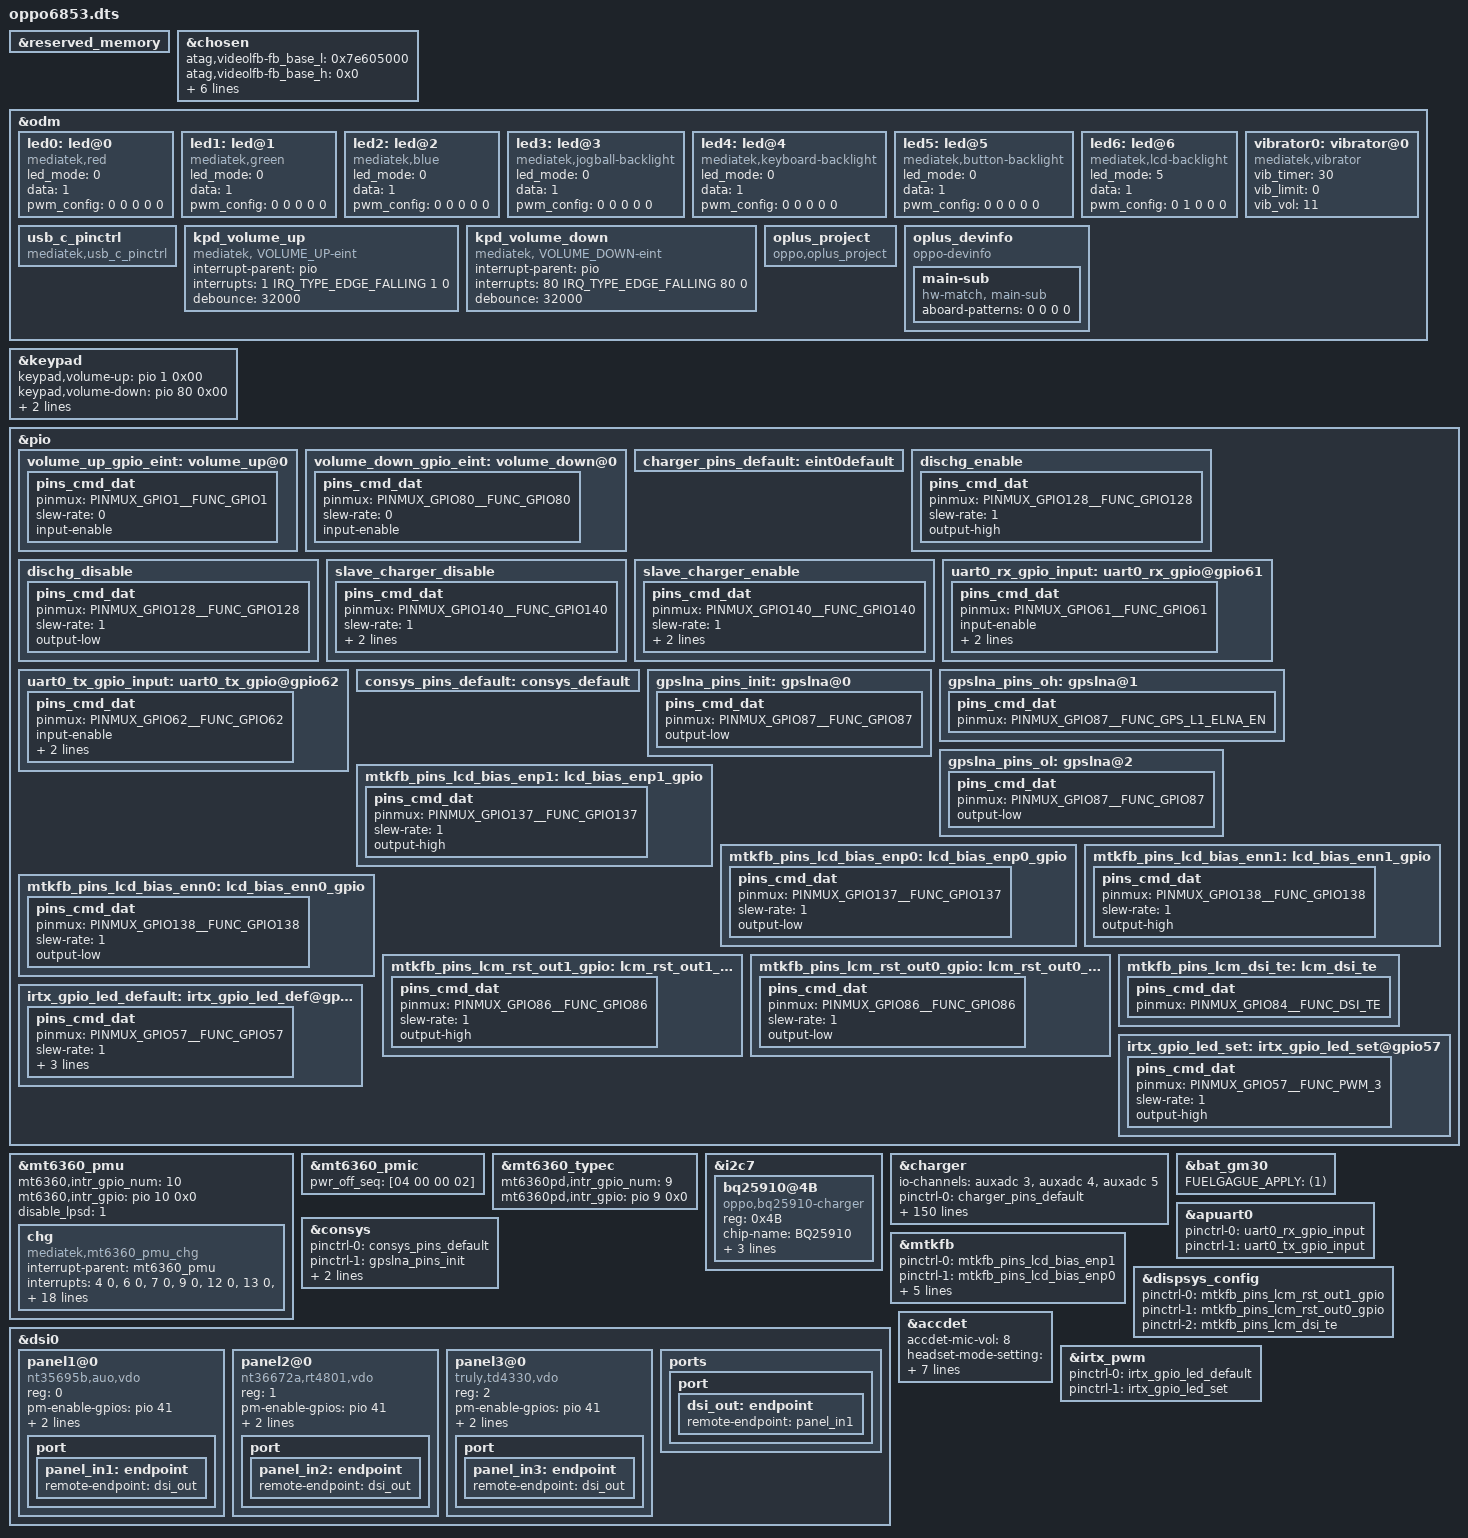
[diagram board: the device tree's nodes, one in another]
/*
 * Mediatek's mt6853 SoC device tree source
 *
 * Copyright (C) 2016 MediaTek Inc.
 *
 * This program is free software; you can redistribute it and/or modify
 * it under the terms of the GNU General Public License version 2 as
 * published by the Free Software Foundation.
 *
 * This program is distributed in the hope that it will be useful,
 * but WITHOUT ANY WARRANTY; without even the implied warranty of
 * MERCHANTABILITY or FITNESS FOR A PARTICULAR PURPOSE.
 * See http://www.gnu.org/licenses/gpl-2.0.html for more details.
 */
/dts-v1/;
/plugin/;
#include <dt-bindings/interrupt-controller/irq.h>
#include <dt-bindings/interrupt-controller/arm-gic.h>
#include <dt-bindings/pinctrl/mt6853-pinfunc.h>

&reserved_memory {
};

/* chosen */
&chosen {

	atag,videolfb-fb_base_l = <0x7e605000>;
	atag,videolfb-fb_base_h = <0x0>;
	atag,videolfb-islcmfound = <1>;
	atag,videolfb-islcm_inited = <0>;
	atag,videolfb-fps= <6000>;
	atag,videolfb-vramSize= <0x1be0000>;
	atag,videolfb-lcmname=
		"nt35595_fhd_dsi_cmd_truly_nt50358_drv";
};

&odm {
	led0:led@0 {
		compatible = "mediatek,red";
		led_mode = <0>;
		data = <1>;
		pwm_config = <0 0 0 0 0>;
	};
	led1:led@1 {
		compatible = "mediatek,green";
		led_mode = <0>;
		data = <1>;
		pwm_config = <0 0 0 0 0>;
	};
	led2:led@2 {
		compatible = "mediatek,blue";
		led_mode = <0>;
		data = <1>;
		pwm_config = <0 0 0 0 0>;
	};
	led3:led@3 {
		compatible = "mediatek,jogball-backlight";
		led_mode = <0>;
		data = <1>;
		pwm_config = <0 0 0 0 0>;
	};
	led4:led@4 {
		compatible = "mediatek,keyboard-backlight";
		led_mode = <0>;
		data = <1>;
		pwm_config = <0 0 0 0 0>;
	};
	led5:led@5 {
		compatible = "mediatek,button-backlight";
		led_mode = <0>;
		data = <1>;
		pwm_config = <0 0 0 0 0>;
	};
	led6:led@6 {
		compatible = "mediatek,lcd-backlight";
		led_mode = <5>;
		data = <1>;
		pwm_config = <0 1 0 0 0>;
	};
	vibrator0:vibrator@0 {
		compatible = "mediatek,vibrator";
		//#ifdef VENDOR_EDIT
		vib_timer = <30>;
		vib_limit = <0>;
		//#else
		//vib_timer = <25>;
		//vib_limit = <9>;
		//#endif /* VENDOR_EDIT */
		//#ifdef VENDOR_EDIT
		vib_vol= <11>;
		//#endif /* VENDOR_EDIT */
	};
	usb_c_pinctrl:usb_c_pinctrl {
		compatible = "mediatek,usb_c_pinctrl";
	};

/*VENDOR_EDIT keypad start*/
	kpd_volume_up:kpd_volume_up {
		compatible = "mediatek, VOLUME_UP-eint";
		interrupt-parent = <&pio>;
		interrupts = <1 IRQ_TYPE_EDGE_FALLING 1 0>;
		debounce = <32000>;
		status = "okay";
	};

	kpd_volume_down:kpd_volume_down {
		compatible = "mediatek, VOLUME_DOWN-eint";
		interrupt-parent = <&pio>;
		interrupts = <80 IRQ_TYPE_EDGE_FALLING 80 0>;
		debounce = <32000>;
		status = "okay";
	};
/*VENDOR_EDIT keypad end*/

	oplus_project:oplus_project {
		compatible = "oppo,oplus_project";
	};
	oplus_devinfo:oplus_devinfo {
		compatible = "oppo-devinfo";

		main-sub {
			compatible = "hw-match, main-sub";
			aboard-patterns = <0 0 0 0>;
			/*main board*/
			//match-projects = <19537 19538 19541 19539>;
		};
	};

};

/*VENDOR_EDIT*/
&keypad {
	keypad,volume-up	= <&pio 1 0x00>;
	keypad,volume-down	= <&pio 80 0x00>;
	pinctrl-names = "volume_up_as_int", "volume_down_as_int";
	pinctrl-0 = <&volume_up_gpio_eint>;
	pinctrl-1 = <&volume_down_gpio_eint>;
	status = "okay";
};
&pio {
	volume_up_gpio_eint:volume_up@0{
		pins_cmd_dat {
			pinmux = <PINMUX_GPIO1__FUNC_GPIO1>;
			slew-rate = <0>;  /*direction 0:in, 1:out*/
			input-enable;
		};
	};

	volume_down_gpio_eint:volume_down@0{
		pins_cmd_dat {
			pinmux = <PINMUX_GPIO80__FUNC_GPIO80>;
			slew-rate = <0>;  /*direction 0:in, 1:out*/
			input-enable;
		};
	};
};
/*VENDOR_EDIT*/
/* Charging Start */

&mt6360_pmu {
	mt6360,intr_gpio_num = <10>; /* direct defined GPIO num */
	mt6360,intr_gpio = <&pio 10 0x0>;
	//#ifdef VENDOR_EDIT
	disable_lpsd = <1>;
};

&mt6360_pmic {
	pwr_off_seq = [04 00 00 02];
};

&mt6360_typec {
	mt6360pd,intr_gpio_num = <9>; /* direct defined GPIO num */
	mt6360pd,intr_gpio = <&pio 9 0x0>;
	//mt6360pd,pcb_gpio = <&pio 57 0x0>;
	//mt6360pd,pcb_gpio_num = <57>;
};

&mt6360_pmu {
	chg {
		compatible = "mediatek,mt6360_pmu_chg";
		interrupt-parent = <&mt6360_pmu>;
		interrupts = <4 0>, <6 0>, <7 0>, <9 0>,
				<12 0>, <13 0>, <14 0>, <15 0>,
				<27 0>, <29 0>, <30 0>, <32 0>,
				<35 0>, <40 0>, <48 0>, <60 0>,
				<53 0>;
		interrupt-names = "chg_treg_evt", "chg_mivr_evt",
				"pwr_rdy_evt", "chg_batsysuv_evt",
				"chg_vsysuv_evt", "chg_vsysov_evt",
				"chg_vbatov_evt", "chg_vbusov_evt",
				"chg_tmri", "chg_adpbadi",
				"chg_rvpi",  "chg_aiccmeasl",
				"wdtmri", "pumpx_donei",
				"attachi", "chrdet_ext_evt",
				"hvdcp_det";
		io-channels = <&adc 0>, <&adc 1>, <&adc 3>, <&adc 4>,
				<&adc 5>, <&adc 6>, <&adc 8>, <&adc 10>;
		io-channel-names = "USBID", "VBUSDIV5", "VSYS", "VBAT",
				"IBUS", "IBAT", "TEMP_JC", "TS";
		chg_name = "primary_chg";
		ichg = <2000000>;               /* uA */
		aicr = <500000>;                /* uA */
		mivr = <4400000>;               /* uV */
		cv = <4350000>;                 /* uA */
		ieoc = <150000>;                /* uA */
		safety_timer = <12>;            /* hour */
		ircmp_resistor = <25000>;       /* uohm */
		ircmp_vclamp = <32000>;         /* uV */
		en_te = <1>;
		en_wdt = <1>;
		aicc_once = <1>;
		post_aicc = <1>;
		batoc_notify = <0>;
	};
};


&i2c7 {
	bq25910@4B{
		status = "okay";
		compatible = "oppo,bq25910-charger";
		reg = <0x4B>;
		chip-name = "BQ25910";

		pinctrl-names = "slave_charger_disable", "slave_charger_enable";
		pinctrl-0 = <&slave_charger_disable>;
		pinctrl-1 = <&slave_charger_enable>;

		qcom,slave-chg-en-gpio = <&pio 140 0x00>;
	};
};


&charger {
	io-channels =  <&auxadc 3>,<&auxadc 4>,
		<&auxadc 5>;
	io-channel-names = "auxadc3-chargeric_temp","auxadc4-usb_temp_v_l",
		"auxadc5-usb_temp_v_r";

	pinctrl-names = "default", "dischg_enable", "dischg_disable";
	pinctrl-0 = <&charger_pins_default>;
	pinctrl-1 = <&dischg_enable>;
	pinctrl-2 = <&dischg_disable>;

	//for oppo chg framework:
	qcom,input_current_charger_ma = <2000>;
        qcom,input_current_usb_ma = <500>;
        qcom,input_current_cdp_ma = <1500>;
        qcom,input_current_led_ma = <1200>;
        qcom,input_current_led_ma_high = <1000>;
        qcom,input_current_led_ma_warm = <1500>;
        qcom,input_current_led_ma_normal = <2000>;
        qcom,input_current_led_ma_forcmcc = <500>;
        qcom,input_current_camera_ma = <2000>;
        qcom,input_current_calling_ma = <1500>;
        qcom,qc_input_current_charger_ma = <2000>;

	qcom,iterm_disabled = <0>;
	qcom,iterm_ma = <200>;
	qcom,recharge-mv = <100>;

	qcom,batt_capacity_mah = <3945>;

	qcom,removed_bat_decidegc = <190>;  /* < -19C */

	qcom,cold_bat_decidegc = <20>;  /* -2C ~ 0C */
        qcom,temp_cold_vfloat_mv = <3980>;
        qcom,temp_cold_fastchg_current_ma = <300>;

        qcom,little_cold_bat_decidegc = <0>;    /* 0C ~ 5C */
        qcom,temp_little_cold_vfloat_mv = <4385>;
        qcom,temp_little_cold_fastchg_current_ma_high = <550>;
        qcom,temp_little_cold_fastchg_current_ma_low = <550>;
        qcom,temp_little_cold_fastchg_current_ma = <550>;
        qcom,qc_temp_little_cold_fastchg_current_ma_high = <1850>;
        qcom,qc_temp_little_cold_fastchg_current_ma_low = <1100>;

	qcom,cool_bat_decidegc = <50>;  /* 5C ~ 12C */
        qcom,temp_cool_vfloat_mv = <4385>;
        qcom,temp_cool_fastchg_current_ma_high = <1100>;
        qcom,temp_cool_fastchg_current_ma_low = <500>;
        qcom,qc_temp_cool_fastchg_current_ma_high = <3400>;
        qcom,qc_temp_cool_fastchg_current_ma_low = <2600>;

        qcom,little_cool_bat_decidegc = <120>;  /* 12C ~ 16C */
        qcom,temp_little_cool_vfloat_mv = <4385>;
        qcom,temp_little_cool_fastchg_current_ma = <1650>;
        qcom,temp_little_cool_fastchg_current_ma_high = <1650>;
	qcom,temp_little_cool_fastchg_current_ma_low = <1650>;
	qcom,qc_temp_little_cool_fastchg_current_ma = <3400>;

        qcom,normal_bat_decidegc = <160>;       /* 16C ~ 45C */
        qcom,temp_normal_fastchg_current_ma = <2600>;
        qcom,temp_normal_vfloat_mv = <4385>;
        qcom,qc_temp_normal_fastchg_current_ma = <2600>;

        qcom,normal_phase1_bat_decidegc = <160>;       /* 16C ~ 22C */
        qcom,temp_normal_phase1_vfloat_mv = <4385>;
        qcom,temp_normal_phase1_fastchg_current_ma = <3400>;

        qcom,normal_phase2_bat_decidegc = <220>;       /* 22C ~ 34C */
        qcom,temp_normal_phase2_vfloat_mv = <4385>;
        qcom,temp_normal_phase2_fastchg_current_ma_high = <3400>;
        qcom,temp_normal_phase2_fastchg_current_ma_low = <3400>;

        qcom,normal_phase3_bat_decidegc = <340>;       /* 34 ~ 37C */
        qcom,temp_normal_phase3_vfloat_mv = <4385>;
        qcom,temp_normal_phase3_fastchg_current_ma_high = <3100>;
        qcom,temp_normal_phase3_fastchg_current_ma_low = <3100>;

        qcom,normal_phase4_bat_decidegc = <370>;       /* 37C ~ 40C */
        qcom,temp_normal_phase4_vfloat_mv = <4385>;
        qcom,temp_normal_phase4_fastchg_current_ma_high = <2300>;
        qcom,temp_normal_phase4_fastchg_current_ma_low = <2300>;

        qcom,normal_phase5_bat_decidegc = <400>;       /* 40C ~ 42C */
        qcom,temp_normal_phase5_vfloat_mv = <4385>;
        qcom,temp_normal_phase5_fastchg_current_ma = <2000>;

        qcom,normal_phase6_bat_decidegc = <420>;       /* 42C ~ 45C */
        qcom,temp_normal_phase6_vfloat_mv = <4385>;
        qcom,temp_normal_phase6_fastchg_current_ma = <1100>;


        qcom,warm_bat_decidegc = <450>;         /* 45C ~ 53C */ /*8pin Bat Vooc project need add 3 degree C*/
        qcom,temp_warm_vfloat_mv = <4130>;
        qcom,temp_warm_fastchg_current_ma = <1100>;
        qcom,temp_warm_fastchg_current_ma_led_on = <500>;
        qcom,qc_temp_warm_fastchg_current_ma = <1100>;

	qcom,hot_bat_decidegc = <530>;  /* > 53C */

	qcom,non_standard_vfloat_mv = <3980>;
	qcom,non_standard_fastchg_current_ma = <512>;

	qcom,short_c_bat_cv_mv = <4330>;
	qcom,short_c_bat_vfloat_mv = <3800>;
	qcom,short_c_bat_fastchg_current_ma = <512>;
	qcom,short_c_bat_vfloat_sw_limit = <3750>;

	qcom,cold_vfloat_sw_limit = <3930>;
	qcom,little_cold_vfloat_sw_limit = <4320>;
	qcom,cool_vfloat_sw_limit = <4320>;
	qcom,little_cool_vfloat_sw_limit = <4320>;
	qcom,normal_vfloat_sw_limit = <4320>;
	qcom,warm_vfloat_sw_limit = <4030>;
	qcom,non_standard_vfloat_sw_limit = <3930>;

	qcom,max_chg_time_sec = <56808>;
	qcom,charger_hv_thr = <10000>;
	qcom,charger_recv_thr = <9700>;
	qcom,charger_lv_thr = <3400>;
	qcom,vbatt_full_thr = <4400>;
	qcom,vbatt_hv_thr = <4500>;

	qcom,vfloat_step_mv = <16>;
	qcom,non_standard_vfloat_over_sw_limit = <3980>;
	qcom,cold_vfloat_over_sw_limit = <3980>;
	qcom,little_cold_vfloat_over_sw_limit = <4390>;
	qcom,cool_vfloat_over_sw_limit = <4390>;
	qcom,little_cool_vfloat_over_sw_limit = <4390>;
	qcom,normal_vfloat_over_sw_limit = <4390>;
	qcom,warm_vfloat_over_sw_limit = <4080>;

	qcom,vbatt_power_off = <3300>;
	qcom,vbatt_soc_1 = <3410>;
	//qcom,vooc_project = <1>;
	qcom,vbatt_num = <1>;

	qcom,normal_vterm_hw_inc = <18>;
	qcom,non_normal_vterm_hw_inc = <18>;

	qcom,overchg_normal_fastchg_ma = <700>;/*16C~35c*/
	qcom,overchg_temp_warm_decidegc = <350>;
	qcom,overchg_warm_fastchg_ma = <750>;/*35C~40c*/
	qcom,overchg_temp_high_decidegc = <400>;

	qcom,overchg_normal_vfloat_sw_limit = <4450>;
	qcom,overchg_temp_normal_vfloat_mv = <4500>;
	qcom,overchg_normal_vfloat_over_sw_limit = <4500>;

	qcom,default_iterm_ma = <200>;
	qcom,default_temp_normal_fastchg_current_ma = <2000>;
	qcom,default_normal_vfloat_sw_limit = <4320>;
	qcom,default_temp_normal_vfloat_mv = <4385>;
	qcom,default_normal_vfloat_over_sw_limit = <4390>;

	//for control:
	//qcom,suspend_after_full;
	qcom,check_batt_full_by_sw;
	qcom,external_gauge;
	qcom,chg_ctrl_by_calling;
	qcom,chg_ctrl_by_lcd;
	qcom,chg_ctrl_by_camera;
	qcom,sw_vfloat_over_protect_enable;

	//for PD9V or QC9V
	qcom,vbatt_pdqc_to_5v_thr = <3400>;
	qcom,dual_charger_support = <1>;
	qcom,slave_pct = <30>;
	qcom,slave_chg_enable_ma = <2500>;
	qcom,slave_chg_disable_ma = <2300>;

	//for step charger
	qcom,step1_time = <600>;		/*10min*/
	qcom,step1_current_ma = <3400>;		/*3400ma*/
	qcom,step2_time = <600>;		/*10min*/
	qcom,step2_current_ma = <3100>;		/*3100ma*/
	qcom,step3_current_ma = <2700>;		/*2700ma*/

	//GPIO config:
	qcom,dischg-gpio = <&pio 128 0x00>;
};
&bat_gm30 {
	FUELGAGUE_APPLY = <(1)>;
};
&pio {
	charger_pins_default: eint0default {
	};

	dischg_enable: dischg_enable {
		pins_cmd_dat {
			pinmux = <PINMUX_GPIO128__FUNC_GPIO128>;
			slew-rate = <1>;//0:input direction 1:output direction
			//bias-pull-up = <00>;
			output-high;
		};
	};

	dischg_disable: dischg_disable {
		pins_cmd_dat {
			pinmux = <PINMUX_GPIO128__FUNC_GPIO128>;
			slew-rate = <1>;
			//bias-pull-down = <00>;
			output-low;
		};
	};

		slave_charger_disable: slave_charger_disable {
                pins_cmd_dat {
                        pinmux = <PINMUX_GPIO140__FUNC_GPIO140>;
                        slew-rate = <1>;//0:input direction 1:output direction
                        bias-pull-up = <00>;
                        output-low;
                };
        };

        slave_charger_enable: slave_charger_enable {
                pins_cmd_dat {
                        pinmux = <PINMUX_GPIO140__FUNC_GPIO140>;
                        slew-rate = <1>;
                        bias-pull-down = <00>;
                        output-high;
                };
        };

};

//#ifdef VENDOR_EDIT
&apuart0 {
	pinctrl-names = "uart0_rx_gpio",
			"uart0_tx_gpio";
	pinctrl-0 = <&uart0_rx_gpio_input>;
	pinctrl-1 = <&uart0_tx_gpio_input>;
	status = "okay";
};

&pio {
	uart0_rx_gpio_input:uart0_rx_gpio@gpio61 {
		pins_cmd_dat {
			pinmux = <PINMUX_GPIO61__FUNC_GPIO61>;
			input-enable;
			slew-rate = <0>;
			bias-disable;
		};
	};
	uart0_tx_gpio_input:uart0_tx_gpio@gpio62 {
		pins_cmd_dat {
			pinmux = <PINMUX_GPIO62__FUNC_GPIO62>;
			input-enable;
			slew-rate = <0>;
			bias-disable;
		};
	};
};

//#endif /* VENDOR_EDIT */

/* Charging end  */
/* USB SWITCH GPIO start */
/*&pio {
	usb_default: usb_default {
	};

	gpio_redriver_c1_init: c1_init {
		pins_cmd_dat {
			pinmux = <PINMUX_GPIO41__FUNC_GPIO41>;
			slew-rate = <1>;
			output-low;
		};
	};

	gpio_redriver_c1_low: c1_low {
		pins_cmd_dat {
			pinmux = <PINMUX_GPIO41__FUNC_GPIO41>;
			slew-rate = <1>;
			output-low;
		};
	};

	gpio_redriver_c1_hiz: c1_highz {
		pins_cmd_dat {
			pinmux = <PINMUX_GPIO41__FUNC_GPIO41>;
			slew-rate= <0>;
			bias-disable;
		};
	};

	gpio_redriver_c1_high: c1_high {
		pins_cmd_dat {
			pinmux = <PINMUX_GPIO41__FUNC_GPIO41>;
			slew-rate = <1>;
			output-high;
		};
	};

	gpio_redriver_c2_init: c2_init {
		pins_cmd_dat {
			pinmux = <PINMUX_GPIO40__FUNC_GPIO40>;
			slew-rate = <1>;
			output-low;
		};
	};

	gpio_redriver_c2_low: c2_low {
		pins_cmd_dat {
			pinmux = <PINMUX_GPIO40__FUNC_GPIO40>;
			slew-rate = <1>;
			output-low;
		};
	};

	gpio_redriver_c2_hiz: c2_highz {
		pins_cmd_dat {
			pinmux = <PINMUX_GPIO40__FUNC_GPIO40>;
			slew-rate= <0>;
			bias-disable;
		};
	};

	gpio_redriver_c2_high: c2_high {
		pins_cmd_dat {
			pinmux = <PINMUX_GPIO40__FUNC_GPIO40>;
			slew-rate = <1>;
			output-high;
		};
	};

	gpio_u3_switch_sel1: u3_sw_sel1 {
		pins_cmd_dat {
			pinmux = <PINMUX_GPIO11__FUNC_GPIO11>;
			slew-rate = <1>;
			output-low;
		};
	};

	gpio_u3_switch_sel2: u3_sw_sel2 {
		pins_cmd_dat {
			pinmux = <PINMUX_GPIO11__FUNC_GPIO11>;
			slew-rate = <1>;
			output-high;
		};
	};

	gpio_u3_switch_enable: u3_sw_en {
	};

	gpio_u3_switch_disable: u3_sw_dis {
	};
};

&usb_c_pinctrl {
	pinctrl-names = "usb_default",
		"redrv_c1_init",
		"redrv_c1_low",
		"redrv_c1_hiz",
		"redrv_c1_high",
		"redrv_c2_init",
		"redrv_c2_low",
		"redrv_c2_hiz",
		"redrv_c2_high",
		"switch_sel1",
		"switch_sel2",
		"switch_enable",
		"switch_disable";

	pinctrl-0 = <&usb_default>;
	pinctrl-1 = <&gpio_redriver_c1_init>;
	pinctrl-2 = <&gpio_redriver_c1_low>;
	pinctrl-3 = <&gpio_redriver_c1_hiz>;
	pinctrl-4 = <&gpio_redriver_c1_high>;
	pinctrl-5 = <&gpio_redriver_c2_init>;
	pinctrl-6 = <&gpio_redriver_c2_low>;
	pinctrl-7 = <&gpio_redriver_c2_hiz>;
	pinctrl-8 = <&gpio_redriver_c2_high>;
	pinctrl-9 = <&gpio_u3_switch_sel1>;
	pinctrl-10 = <&gpio_u3_switch_sel2>;
	pinctrl-11 = <&gpio_u3_switch_enable>;
	pinctrl-12 = <&gpio_u3_switch_disable>;
	status = "okay";

	usb_switch-data {
		en_pin_num = <0>;
		en_pin_val = <0>;
		sel_pin_num = <11>;
		sel_pin_val = <1>;
		c1_pin_num = <41>;
		c1_pin_val = <2>;
		c2_pin_num = <40>;
		c2_pin_val = <1>;
	};
};*/
/* USB SWITCH GPIO end */


/* CONSYS GPIO standardization */
&pio {
	consys_pins_default: consys_default {
	};
	gpslna_pins_init: gpslna@0 {
		pins_cmd_dat {
			pinmux = <PINMUX_GPIO87__FUNC_GPIO87>;
			output-low;
		};
	};
	gpslna_pins_oh: gpslna@1 {
		pins_cmd_dat {
			pinmux = <PINMUX_GPIO87__FUNC_GPS_L1_ELNA_EN>;
		};
	};
	gpslna_pins_ol: gpslna@2 {
		pins_cmd_dat {
			pinmux = <PINMUX_GPIO87__FUNC_GPIO87>;
			output-low;
		};
	};
};

&consys {
	pinctrl-names = "default", "gps_lna_state_init",
		"gps_lna_state_oh", "gps_lna_state_ol";
	pinctrl-0 = <&consys_pins_default>;
	pinctrl-1 = <&gpslna_pins_init>;
	pinctrl-2 = <&gpslna_pins_oh>;
	pinctrl-3 = <&gpslna_pins_ol>;
	status = "okay";
};
/* CONSYS end */

#include "mediatek/cust_mt6853_touch_1080x1920.dtsi"
#include "mediatek/cust_mt6853_camera.dtsi"
#include <oppo6853/cust.dtsi>
/* DISPSYS GPIO standardization */

#ifndef CONFIG_FPGA_EARLY_PORTING
&pio {
	mtkfb_pins_lcd_bias_enp1: lcd_bias_enp1_gpio {
		pins_cmd_dat {
			pinmux = <PINMUX_GPIO137__FUNC_GPIO137>;
			slew-rate = <1>;
			output-high;
		};
	};

	mtkfb_pins_lcd_bias_enp0: lcd_bias_enp0_gpio {
		pins_cmd_dat {
			pinmux = <PINMUX_GPIO137__FUNC_GPIO137>;
			slew-rate = <1>;
			output-low;
		};
	};

	mtkfb_pins_lcd_bias_enn1: lcd_bias_enn1_gpio {
		pins_cmd_dat {
			pinmux = <PINMUX_GPIO138__FUNC_GPIO138>;
			slew-rate = <1>;
			output-high;
		};
	};

	mtkfb_pins_lcd_bias_enn0: lcd_bias_enn0_gpio {
		pins_cmd_dat {
			pinmux = <PINMUX_GPIO138__FUNC_GPIO138>;
			slew-rate = <1>;
			output-low;
		};
	};

	mtkfb_pins_lcm_rst_out1_gpio: lcm_rst_out1_gpio {
		pins_cmd_dat {
			pinmux = <PINMUX_GPIO86__FUNC_GPIO86>;
			slew-rate = <1>;
			output-high;
		};
	};

	mtkfb_pins_lcm_rst_out0_gpio: lcm_rst_out0_gpio {
		pins_cmd_dat {
			pinmux = <PINMUX_GPIO86__FUNC_GPIO86>;
			slew-rate = <1>;
			output-low;
		};
	};
	mtkfb_pins_lcm_dsi_te: lcm_dsi_te {
		pins_cmd_dat {
			pinmux = <PINMUX_GPIO84__FUNC_DSI_TE>;
		};
	};
};

&mtkfb {
	pinctrl-names = "lcd_bias_enp1_gpio", "lcd_bias_enp0_gpio",
		"lcd_bias_enn1_gpio", "lcd_bias_enn0_gpio",
		"lcm_rst_out1_gpio", "lcm_rst_out0_gpio",
		"mode_te_te";
	pinctrl-0 = <&mtkfb_pins_lcd_bias_enp1>;
	pinctrl-1 = <&mtkfb_pins_lcd_bias_enp0>;
	pinctrl-2 = <&mtkfb_pins_lcd_bias_enn1>;
	pinctrl-3 = <&mtkfb_pins_lcd_bias_enn0>;
	pinctrl-4 = <&mtkfb_pins_lcm_rst_out1_gpio>;
	pinctrl-5 = <&mtkfb_pins_lcm_rst_out0_gpio>;
	pinctrl-6 = <&mtkfb_pins_lcm_dsi_te>;
	status = "okay";
};
&dispsys_config {
	pinctrl-names =
		"lcm_rst_out1_gpio", "lcm_rst_out0_gpio",
		"mode_te_te";
	pinctrl-0 = <&mtkfb_pins_lcm_rst_out1_gpio>;
	pinctrl-1 = <&mtkfb_pins_lcm_rst_out0_gpio>;
	pinctrl-2 = <&mtkfb_pins_lcm_dsi_te>;
	status = "okay";
};
&dsi0 {
	status = "okay";
	#address-cells = <1>;
	#size-cells = <0>;
	panel1@0 {
		compatible = "nt35695b,auo,vdo";
		reg = <0>;
		pm-enable-gpios = <&pio 41 0>;
		reset-gpios = <&pio 86 0>;
		bias-gpios = <&pio 137 0>,
			<&pio 138 0>;
		pinctrl-names = "default";
		port {
			panel_in1: endpoint {
				remote-endpoint = <&dsi_out>;
			};
		};
	};
	panel2@0 {
		compatible = "nt36672a,rt4801,vdo";
		reg = <1>;
		pm-enable-gpios = <&pio 41 0>;
		reset-gpios = <&pio 86 0>;
		bias-gpios = <&pio 137 0>,
			<&pio 138 0>;
		pinctrl-names = "default";
		port {
			panel_in2: endpoint {
				remote-endpoint = <&dsi_out>;
			};
		};
	};
	panel3@0 {
		compatible = "truly,td4330,vdo";
		reg = <2>;
		pm-enable-gpios = <&pio 41 0>;
		reset-gpios = <&pio 86 0>;
		bias-gpios = <&pio 137 0>,
			<&pio 138 0>;
		pinctrl-names = "default";
		port {
			panel_in3: endpoint {
				remote-endpoint = <&dsi_out>;
			};
		};
	};
	ports {
		port {
			dsi_out: endpoint {
				remote-endpoint = <&panel_in1>;
			};
		};
	};
};

/* accdet start */
&accdet {
	/* accdet micbias voltage: 0x09:2.85v 0x08:2.8v 0x07,
	 * 2.7v;0x05,2.5v;0x02,1.9v
	 */
	accdet-mic-vol = <8>;
	/* accdet pwm_width, pwm_thresh, fall_delay, rise_delay
	 * debounce0, debounce1, debounce3, debounce4
	 * eint pwm_width, eint pwm_thresh
	 * eint deb(debounce0, debounce1, debounce2, debounce3), inv_debounce
	 */
	headset-mode-setting = <0x500 0x500 1 0x1f0
				0x800 0x800 0x20 0x44
				0x4 0x1
				0x5 0x3 0x3 0x5 0xe>;
	accdet-plugout-debounce = <1>;
	/*1:ACC mode, 2:low cost without in bias, 6:low cost with in bias*/
	accdet-mic-mode = <2>;
	/*0--MD_MAX--UP_MAX--DW_MAX*/
	headset-three-key-threshold = <0 80 220 400>;
	headset-three-key-threshold-CDD = <0 121 192 600>;
	/*0--MD_MAX--VOICE_MAX--UP_MAX--DW_MAX*/
	headset-four-key-threshold = <0 58 121 192 400>;

	/* select VTH to 2v and 500k, use internal resitance */
	eint_use_ext_res = <0>;
	status = "okay";
};
/* accdet end */

/* IRTX GPIO Start */
&irtx_pwm {
	pinctrl-names = "irtx_gpio_led_default", "irtx_gpio_led_set";
	pinctrl-0 = <&irtx_gpio_led_default>;
	pinctrl-1 = <&irtx_gpio_led_set>;
	status = "okay";
};
&pio {
	/* IRTX GPIO Settings -Start */
	/* default: GPIO0, output, high */
	irtx_gpio_led_default:irtx_gpio_led_def@gpio57 {
		pins_cmd_dat {
			pinmux = <PINMUX_GPIO57__FUNC_GPIO57>;
			slew-rate = <1>;
			bias-disable;
			output-low;
			input-schmitt-enable = <0>;
		};
	};

	irtx_gpio_led_set:irtx_gpio_led_set@gpio57 {
		pins_cmd_dat {
			pinmux = <PINMUX_GPIO57__FUNC_PWM_3>;
			slew-rate = <1>;
			output-high;
		};
	};
}; /* IRTX GPIO Settings -End */

#endif

/*End of this file, DO NOT ADD ANYTHING HERE*/

